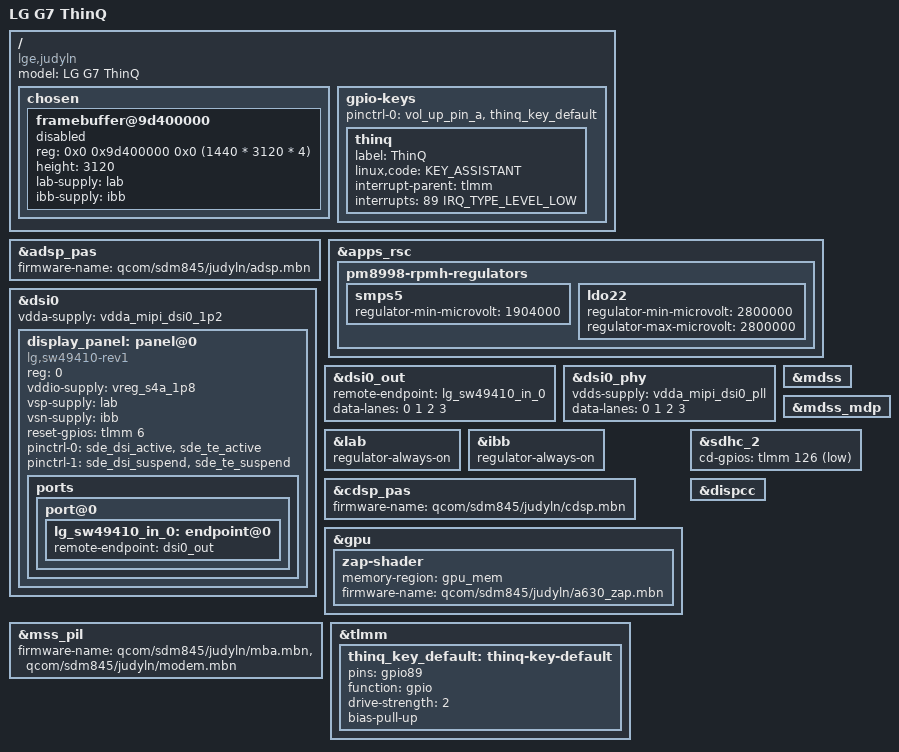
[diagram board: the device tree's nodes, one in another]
// SPDX-License-Identifier: GPL-2.0
/*
 * SDM845 LG G7 (judyln) device tree.
 *
 * Copyright (c) 2021, The Linux Foundation. All rights reserved.
 */

/dts-v1/;

#include "sdm845-lge-common.dtsi"

/ {
	model = "LG G7 ThinQ";
	compatible = "lge,judyln", "qcom,sdm845";

	chosen {
		framebuffer@9d400000 {
			status = "disabled";
			reg = <0x0 0x9d400000 0x0 (1440 * 3120 * 4)>;
			height = <3120>;
			lab-supply = <&lab>;
			ibb-supply = <&ibb>;
		};
	};

	/* Additional ThinQ key */
	gpio-keys {
		pinctrl-0 = <&vol_up_pin_a &thinq_key_default>;

		thinq {
			label = "ThinQ";
			linux,code = <KEY_ASSISTANT>;
			interrupt-parent = <&tlmm>;
			interrupts = <89 IRQ_TYPE_LEVEL_LOW>;
		};
	};
};

&adsp_pas {
	firmware-name = "qcom/sdm845/judyln/adsp.mbn";
};

&apps_rsc {
	pm8998-rpmh-regulators {
		smps5 {
			regulator-min-microvolt = <1904000>;
		};

		ldo22 {
			regulator-min-microvolt = <2800000>;
			regulator-max-microvolt = <2800000>;
		};
	};
};

&dsi0 {
	status = "okay";
	vdda-supply = <&vdda_mipi_dsi0_1p2>;

	display_panel: panel@0 {
		status = "okay";
		compatible = "lg,sw49410-rev1";
		reg = <0>;
		vddio-supply = <&vreg_s4a_1p8>;
		vsp-supply = <&lab>;
		vsn-supply = <&ibb>;

		reset-gpios = <&tlmm 6 GPIO_ACTIVE_HIGH>;

		pinctrl-names = "panel_active", "panel_suspend";
		pinctrl-0 = <&sde_dsi_active &sde_te_active>;
		pinctrl-1 = <&sde_dsi_suspend &sde_te_suspend>;

		ports {
			port@0 {
				lg_sw49410_in_0: endpoint@0 {
					remote-endpoint = <&dsi0_out>;
				};
			};

			/*
			port@1 {
				lg_sw49410_in_1: endpoint@1 {
					remote-endpoint = <&dsi1_out_panel>;
				};
			};
			*/
		};
	};
};
/*
&dsi1 {
	status = "okay";

	ports {
		mipi_dsi1_out: port@1 {
			dsi1_out_panel: endpoint {
				remote-endpoint = <&lg_sw49410_in_1>;
			};
		};
	};
};
*/

&dsi0_out {
	remote-endpoint = <&lg_sw49410_in_0>;
	data-lanes = <0 1 2 3>;
};

&dsi0_phy {
	status = "okay";
	vdds-supply = <&vdda_mipi_dsi0_pll>;
	data-lanes = <0 1 2 3>;
};
/*
&dsi1_phy {
	status = "okay";
	vdds-supply = <&vdda_mipi_dsi1_pll>;
	data-lanes = <0 1 2 3>;
};
*/
&mdss {
	status = "okay";
};

&mdss_mdp {
	status = "okay";
};

&lab {
	regulator-always-on;
};

&ibb {
	regulator-always-on;
};

&cdsp_pas {
	firmware-name = "qcom/sdm845/judyln/cdsp.mbn";
};

&gpu {
	status = "okay";

	//regulator-names = "vddcx", "vdd";

	/* GDSC oxili regulators */
	//vddcx-supply = <&vph_pwr>;
	//vdd-supply = <&vph_pwr>;

	zap-shader {
		memory-region = <&gpu_mem>;
		firmware-name = "qcom/sdm845/judyln/a630_zap.mbn";
	};
};

//&soc {
//	/* GDSCs in Graphics CC */
//	gpu_cx_hw_ctrl: syscon@0x5091540 {
//		compatible = "syscon";
//		reg = <0x5091540 0x04>;
//		//phandle = <0x1a>;
//	};
//
//	gpu_gx_domain_addr: syscon@0x5091508 {
//		compatible = "syscon";
//		reg = <0x5091508 0x4>;
//	};
//
//	gpu_gx_sw_reset: syscon@0x5091008 {
//		compatible = "syscon";
//		reg = <0x5091008 0x4>;
//	};
//
//	rpmh-regulator-mxlvl {
//		compatible = "qcom,rpmh-arc-regulator";
//		//mboxes = <&apps_rsc 0>;
//		qcom,resource-name = "mx.lvl";
//		pm8998_s6_level: regulator-s6-level {
//			regulator-name = "pm8998_s6_level";
//			qcom,set = <3>;
//			regulator-min-microvolt = <1>;
//			regulator-max-microvolt = <65536>;
//		};
//
//		pm8998_s6_level_ao: regulator-s6-level-ao {
//			regulator-name = "pm8998_s6_level_ao";
//			qcom,set = <1>;
//			regulator-min-microvolt = <1>;
//			regulator-max-microvolt = <65536>;
//		};
//	};
//
//	rpmh-regulator-cxlvl {
//		compatible = "qcom,rpmh-arc-regulator";
//		//mboxes = <&apps_rsc 0>;
//		qcom,resource-name = "cx.lvl";
//		qcom,send-defaults;
//		pm8998_s9_level-parent-supply = <&pm8998_s6_level>;
//		pm8998_s9_level_ao-parent-supply = <&pm8998_s6_level_ao>;
//			pm8998_s9_level: regulator-s9-level {
//					regulator-name = "pm8998_s9_level";
//					qcom,set = <3>;
//					regulator-min-microvolt = <1>;
//					regulator-max-microvolt = <65536>;
//					qcom,init-voltage-level = <385>;
//				};
//
//			pm8998_s9_level_ao: regulator-s9-level-ao {
//				regulator-name = "pm8998_s9_level_ao";
//				qcom,set = <1>;
//				regulator-min-microvolt = <1>;
//				regulator-max-microvolt = <65536>;
//			};
//	};
//
//	rpmh-regulator-gfxlvl {
//		compatible = "qcom,rpmh-arc-regulator";
//		//mboxes = <&apps_rsc 0>;
//		qcom,resource-name = "gfx.lvl";
//		pm8005_s1_level: regulator-s1-level {
//			regulator-name = "pm8005_s1_level";
//			qcom,set = <3>;
//			regulator-min-microvolt = <49>;
//			regulator-max-microvolt = <65536>;
//			qcom,init-voltage-level = <49>;
//		};
//	};
//
//	gpu_cx_gdsc: qcom,gdsc@0x509106c {
//		compatible = "qcom,gdsc";
//		regulator-name = "gpu_cx_gdsc";
//		reg = <0x509106c 0x04>;
//		hw-ctrl-addr = <&gpu_cx_hw_ctrl>;
//		qcom,no-status-check-on-disable;
//		qcom,gds-timeout = <500>;
//		qcom,clk-dis-wait-val = <8>;
//		status = "ok";
//		parent-supply = <&vph_pwr>;
//		vdd_parent-supply = <&vph_pwr>;
//		//phandle = <0x1a4>;
//	};
//
//	gpu_gx_gdsc: qcom,gdsc@0x509100c {
//		compatible = "qcom,gdsc";
//		regulator-name = "gpu_gx_gdsc";
//		reg = <0x509100c 0x04>;
//		qcom,poll-cfg-gdscr;
//		status = "ok";
//		clock-names = "core_root_clk";
//		clocks = <&gpucc 2>;
//		qcom,force-enable-root-clk;
//		parent-supply = <&vph_pwr>;
//		domain-addr = <&gpu_gx_domain_addr>;
//		sw-reset = <&gpu_gx_domain_addr>;
//		qcom,reset-aon-logic;
//		//phandle = <0x2a8>;
//	};
//};

&mss_pil {
	firmware-name = "qcom/sdm845/judyln/mba.mbn", "qcom/sdm845/judyln/modem.mbn";
};

&sdhc_2 {
	cd-gpios = <&tlmm 126 GPIO_ACTIVE_LOW>; 
};

&dispcc {
  status = "okay";
};

&tlmm {
	thinq_key_default: thinq-key-default {
		pins = "gpio89";
		function = "gpio";

		drive-strength = <2>;
		bias-pull-up;
	};
};
